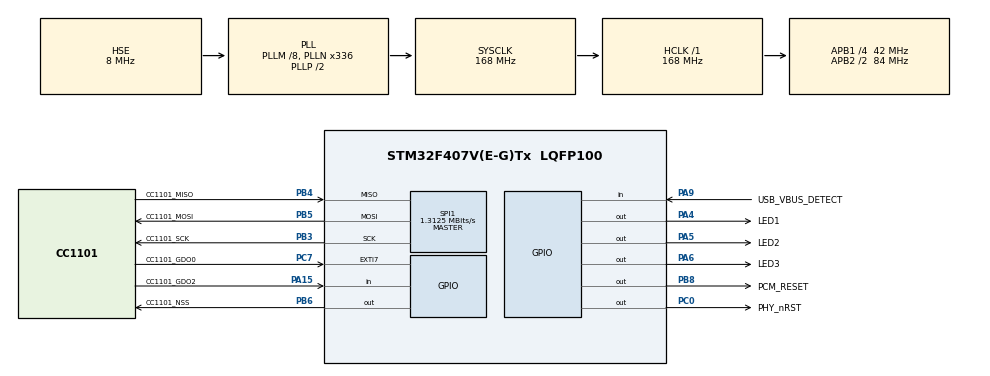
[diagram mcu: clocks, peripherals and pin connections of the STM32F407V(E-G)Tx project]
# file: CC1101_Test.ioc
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Mcu.Family=STM32F4
Mcu.Name=STM32F407V(E-G)Tx
Mcu.Package=LQFP100
NVIC.EXTI9_5_IRQn=true\:0\:0\:false\:false\:true\:true
NVIC.PriorityGroup=NVIC_PRIORITYGROUP_4
NVIC.TIM1_UP_TIM10_IRQn=true\:0\:0\:false\:false\:true\:false
NVIC.TimeBase=TIM1_UP_TIM10_IRQn
NVIC.TimeBaseIP=TIM1
PA15.GPIO_Label=CC1101_GDO2
PA15.Signal=GPIO_Input
PA4.GPIO_Label=LED1
PA4.Signal=GPIO_Output
PA5.GPIO_Label=LED2
PA5.Signal=GPIO_Output
PA6.GPIO_Label=LED3
PA6.Signal=GPIO_Output
PA9.GPIO_Label=USB_VBUS_DETECT
PA9.Signal=GPIO_Input
PB3.GPIO_Label=CC1101_SCK
PB3.Mode=Full_Duplex_Master
PB3.Signal=SPI1_SCK
PB4.GPIO_Label=CC1101_MISO
PB4.Mode=Full_Duplex_Master
PB4.Signal=SPI1_MISO
PB5.GPIO_Label=CC1101_MOSI
PB5.Mode=Full_Duplex_Master
PB5.Signal=SPI1_MOSI
PB6.GPIO_Label=CC1101_NSS
PB6.GPIO_Speed=GPIO_SPEED_FREQ_VERY_HIGH
PB6.Signal=GPIO_Output
PB8.GPIO_Label=PCM_RESET
PB8.Signal=GPIO_Output
PC0.GPIO_Label=PHY_nRST
PC0.Signal=GPIO_Output
PC7.GPIO_Label=CC1101_GDO0
PC7.GPIO_ModeDefaultEXTI=GPIO_MODE_IT_RISING_FALLING
PC7.Signal=GPXTI7
PH0-OSC_IN.Mode=HSE-External-Oscillator
PH0-OSC_IN.Signal=RCC_OSC_IN
PH1-OSC_OUT.Mode=HSE-External-Oscillator
PH1-OSC_OUT.Signal=RCC_OSC_OUT
ProjectManager.HeapSize=0x400
ProjectManager.StackSize=0x400
ProjectManager.TargetToolchain=Makefile
RCC.48MHZClocksFreq_Value=48000000
RCC.AHBFreq_Value=168000000
RCC.APB1CLKDivider=RCC_HCLK_DIV4
RCC.APB1Freq_Value=42000000
RCC.APB1TimFreq_Value=84000000
RCC.APB2CLKDivider=RCC_HCLK_DIV2
RCC.APB2Freq_Value=84000000
RCC.APB2TimFreq_Value=168000000
RCC.CortexFreq_Value=168000000
RCC.HCLKFreq_Value=168000000
RCC.HSE_VALUE=8000000
RCC.HSI_VALUE=16000000
RCC.LSE_VALUE=32768
RCC.PLLI2SN=100
RCC.PLLM=8
RCC.PLLN=336
RCC.PLLQ=7
RCC.PLLSourceVirtual=RCC_PLLSOURCE_HSE
RCC.SYSCLKFreq_VALUE=168000000
RCC.SYSCLKSource=RCC_SYSCLKSOURCE_PLLCLK
RCC.VCOOutputFreq_Value=336000000
SPI1.BaudRatePrescaler=SPI_BAUDRATEPRESCALER_64
SPI1.CalculateBaudRate=1.3125 MBits/s
SPI1.Direction=SPI_DIRECTION_2LINES
SPI1.Mode=SPI_MODE_MASTER
SPI1.VirtualType=VM_MASTER
TIM3.Period=0xffff
TIM3.Prescaler=83
VP_CRC_VS_CRC.Mode=CRC_Activate
VP_RNG_VS_RNG.Mode=RNG_Activate
VP_RTC_VS_RTC_Activate.Mode=RTC_Enabled
VP_SYS_VS_tim1.Mode=TIM1
VP_TIM3_VS_ClockSourceINT.Mode=Internal
board=custom

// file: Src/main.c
/* USER CODE BEGIN Header */
/**
  ******************************************************************************
  * @file           : main.c
  * @brief          : Main program body
  ******************************************************************************
  * This notice applies to any and all portions of this file
  * that are not between comment pairs USER CODE BEGIN and
  * USER CODE END. Other portions of this file, whether
  * inserted by the user or by software development tools
  * are owned by their respective copyright owners.
  *
  * Copyright (c) 2019 STMicroelectronics International N.V.
  * All rights reserved.
  *
  * Redistribution and use in source and binary forms, with or without
  * modification, are permitted, provided that the following conditions are met:
  *
  * 1. Redistribution of source code must retain the above copyright notice,
  *    this list of conditions and the following disclaimer.
  * 2. Redistributions in binary form must reproduce the above copyright notice,
  *    this list of conditions and the following disclaimer in the documentation
  *    and/or other materials provided with the distribution.
  * 3. Neither the name of STMicroelectronics nor the names of other
  *    contributors to this software may be used to endorse or promote products
  *    derived from this software without specific written permission.
  * 4. This software, including modifications and/or derivative works of this
  *    software, must execute solely and exclusively on microcontroller or
  *    microprocessor devices manufactured by or for STMicroelectronics.
  * 5. Redistribution and use of this software other than as permitted under
  *    this license is void and will automatically terminate your rights under
  *    this license.
  *
  * THIS SOFTWARE IS PROVIDED BY STMICROELECTRONICS AND CONTRIBUTORS "AS IS"
  * AND ANY EXPRESS, IMPLIED OR STATUTORY WARRANTIES, INCLUDING, BUT NOT
  * LIMITED TO, THE IMPLIED WARRANTIES OF MERCHANTABILITY, FITNESS FOR A
  * PARTICULAR PURPOSE AND NON-INFRINGEMENT OF THIRD PARTY INTELLECTUAL PROPERTY
  * RIGHTS ARE DISCLAIMED TO THE FULLEST EXTENT PERMITTED BY LAW. IN NO EVENT
  * SHALL STMICROELECTRONICS OR CONTRIBUTORS BE LIABLE FOR ANY DIRECT, INDIRECT,
  * INCIDENTAL, SPECIAL, EXEMPLARY, OR CONSEQUENTIAL DAMAGES (INCLUDING, BUT NOT
  * LIMITED TO, PROCUREMENT OF SUBSTITUTE GOODS OR SERVICES; LOSS OF USE, DATA,
  * OR PROFITS; OR BUSINESS INTERRUPTION) HOWEVER CAUSED AND ON ANY THEORY OF
  * LIABILITY, WHETHER IN CONTRACT, STRICT LIABILITY, OR TORT (INCLUDING
  * NEGLIGENCE OR OTHERWISE) ARISING IN ANY WAY OUT OF THE USE OF THIS SOFTWARE,
  * EVEN IF ADVISED OF THE POSSIBILITY OF SUCH DAMAGE.
  *
  ******************************************************************************
  */
/* USER CODE END Header */

#include "main.h"
#include "crc.h"
#include "rng.h"
#include "rtc.h"
#include "spi.h"
#include "tim.h"
#include "gpio.h"

/* USER CODE BEGIN Includes */
#include "cc1101.h"
#include "decoder.h"
/* USER CODE END Includes */

void SystemClock_Config(void);

int main(void)
{

  /* MCU Configuration--------------------------------------------------------*/

  /* Reset of all peripherals, Initializes the Flash interface and the Systick. */
  HAL_Init();

  /* Configure the system clock */
  SystemClock_Config();

  /* Initialize all configured peripherals */
  MX_GPIO_Init();
  MX_RNG_Init();
  MX_RTC_Init();
  MX_SPI1_Init();
  MX_CRC_Init();
  MX_TIM3_Init();
  /* USER CODE BEGIN 2 */
  Decoder_Init();

  /* USER CODE END 2 */

  /* Infinite loop */
  while (1)
  {

  }
}

void SystemClock_Config(void)
{
  RCC_OscInitTypeDef RCC_OscInitStruct = {0};
  RCC_ClkInitTypeDef RCC_ClkInitStruct = {0};
  RCC_PeriphCLKInitTypeDef PeriphClkInitStruct = {0};

  /**Configure the main internal regulator output voltage
  */
  __HAL_RCC_PWR_CLK_ENABLE();
  __HAL_PWR_VOLTAGESCALING_CONFIG(PWR_REGULATOR_VOLTAGE_SCALE1);
  /**Initializes the CPU, AHB and APB busses clocks
  */
  RCC_OscInitStruct.OscillatorType = RCC_OSCILLATORTYPE_LSI|RCC_OSCILLATORTYPE_HSE;
  RCC_OscInitStruct.HSEState = RCC_HSE_ON;
  RCC_OscInitStruct.LSIState = RCC_LSI_ON;
  RCC_OscInitStruct.PLL.PLLState = RCC_PLL_ON;
  RCC_OscInitStruct.PLL.PLLSource = RCC_PLLSOURCE_HSE;
  RCC_OscInitStruct.PLL.PLLM = 8;
  RCC_OscInitStruct.PLL.PLLN = 336;
  RCC_OscInitStruct.PLL.PLLP = RCC_PLLP_DIV2;
  RCC_OscInitStruct.PLL.PLLQ = 7;
  if (HAL_RCC_OscConfig(&RCC_OscInitStruct) != HAL_OK)
  {
    Error_Handler();
  }
  /**Initializes the CPU, AHB and APB busses clocks
  */
  RCC_ClkInitStruct.ClockType = RCC_CLOCKTYPE_HCLK|RCC_CLOCKTYPE_SYSCLK
                              |RCC_CLOCKTYPE_PCLK1|RCC_CLOCKTYPE_PCLK2;
  RCC_ClkInitStruct.SYSCLKSource = RCC_SYSCLKSOURCE_PLLCLK;
  RCC_ClkInitStruct.AHBCLKDivider = RCC_SYSCLK_DIV1;
  RCC_ClkInitStruct.APB1CLKDivider = RCC_HCLK_DIV4;
  RCC_ClkInitStruct.APB2CLKDivider = RCC_HCLK_DIV2;

  if (HAL_RCC_ClockConfig(&RCC_ClkInitStruct, FLASH_LATENCY_5) != HAL_OK)
  {
    Error_Handler();
  }
  PeriphClkInitStruct.PeriphClockSelection = RCC_PERIPHCLK_RTC;
  PeriphClkInitStruct.RTCClockSelection = RCC_RTCCLKSOURCE_LSI;
  if (HAL_RCCEx_PeriphCLKConfig(&PeriphClkInitStruct) != HAL_OK)
  {
    Error_Handler();
  }
}

/* USER CODE BEGIN 4 */
void HAL_GPIO_EXTI_Callback(uint16_t GPIO_Pin)
{
  if (GPIO_Pin == CC1101_GDO0_Pin) {
    Decoder_Edge_Callback();
  }
}
/* USER CODE END 4 */

void HAL_TIM_PeriodElapsedCallback(TIM_HandleTypeDef *htim)
{
  if (htim->Instance == TIM1) {
    HAL_IncTick();
  }
}

void Error_Handler(void)
{
  while(1)
  {
  }
}

/************************ (C) COPYRIGHT STMicroelectronics *****END OF FILE****/
